# PIC32MK0256GPG064 register map
Vendor: Microchip
Registers are 32-bit, read-write, reset 0x0 unless marked. A register's access mark holds for its fields unless they carry their own. Addresses are absolute, and some are shared; only a register's first bit layout is shown; [hi:lo] are bit positions; {n}, {i} and the like mark numbered series.

## icd_jtag_bvci_upb
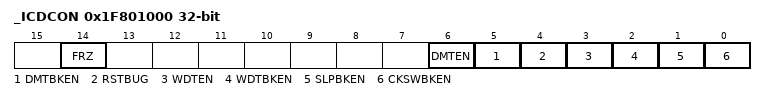
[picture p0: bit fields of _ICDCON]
0x1F801000 _ICDCON
  [14] FRZ, [6] DMTEN, [5] DMTBKEN, [4] RSTBUG, [3] WDTEN, [2] WDTBKEN, [1] SLPBKEN, [0] CKSWBKEN

## _DDPSTAT
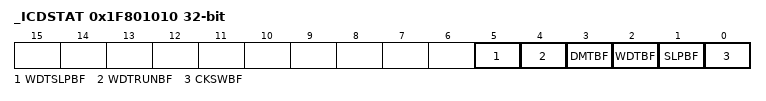
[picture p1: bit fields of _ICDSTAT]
0x1F801010 _ICDSTAT
  [5] WDTSLPBF, [4] WDTRUNBF, [3] DMTBF, [2] WDTBF, [1] SLPBF, [0] CKSWBF

## CRU
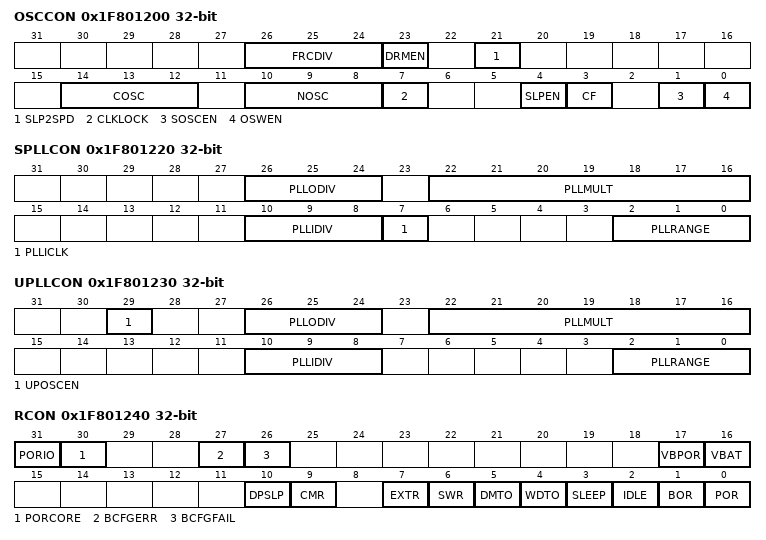
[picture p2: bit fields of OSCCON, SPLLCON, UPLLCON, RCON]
0x1F801200 OSCCON reset not defined — (power-on value -----0000-x------000-xxx0--00-x0)
  [26:24] FRCDIV, [23] DRMEN, [21] SLP2SPD, [14:12] COSC ro, [10:8] NOSC, [7] CLKLOCK, [4] SLPEN, [3] CF, [1] SOSCEN, [0] OSWEN
0x1F801210 OSCTUN
  [5:0] TUN
0x1F801220 SPLLCON reset not defined — (power-on value -----001-xxxxxxx-----xxx0----xxx)
  [26:24] PLLODIV, [22:16] PLLMULT, [10:8] PLLIDIV, [7] PLLICLK, [2:0] PLLRANGE
0x1F801230 UPLLCON reset not defined — (power-on value --x--001-xxxxxxx-----001-----xxx)
  [29] UPOSCEN, [26:24] PLLODIV, [22:16] PLLMULT, [10:8] PLLIDIV, [2:0] PLLRANGE
0x1F801240 RCON reset not defined — (power-on value 00--xx---------------x0-00000011)
  [31] PORIO
  [30] PORCORE
  [27] BCFGERR — Primary Configuration Registers Error Flag bit
    1=An error occurred during a read of the primary configuration registers; 0=No error occurred during a read of the primary configuration registers
  [26] BCFGFAIL — Primary/Secondary Configuration Registers Error Flag bit
    1=An error occurred during a read of the primary and alternate configuration registers; 0=No error occurred during a read of the primary and alternate configuration registers
  [17] VBPOR
  [16] VBAT
  [10] DPSLP
  [9] CMR
  [7] EXTR
  [6] SWR
  [5] DMTO
  [4] WDTO
  [3] SLEEP
  [2] IDLE
  [1] BOR
  [0] POR
0x1F801250 RSWRST wo
  [0] SWRST
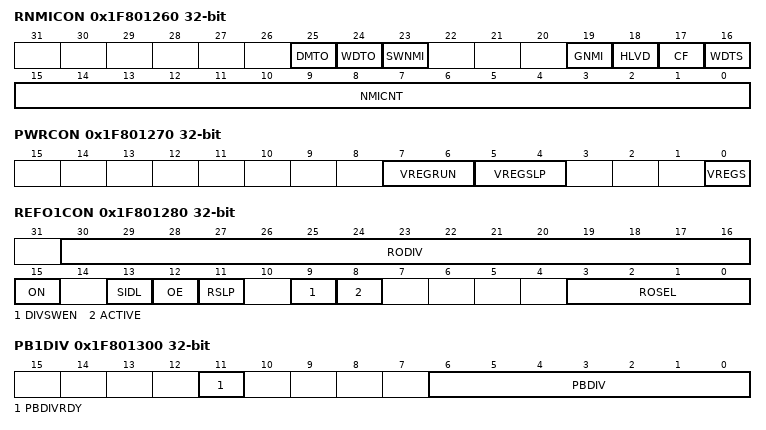
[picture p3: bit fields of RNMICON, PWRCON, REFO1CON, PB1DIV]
0x1F801260 RNMICON reset not defined — (power-on value ------0x0---0-000000000000000000)
  [25] DMTO, [24] WDTO, [23] SWNMI, [19] GNMI, [18] HLVD, [17] CF, [16] WDTS, [15:0] NMICNT
0x1F801270 PWRCON reset not defined — (power-on value ------------------------xxxx---0)
  [7:6] VREGRUN, [5:4] VREGSLP, [0] VREGS
0x1F801280 REFO1CON
  [30:16] RODIV, [15] ON, [13] SIDL, [12] OE, [11] RSLP, [9] DIVSWEN, [8] ACTIVE ro, [3:0] ROSEL
0x1F801290 REFO1TRIM
  [31:23] ROTRIM
0x1F801300 PB1DIV reset not defined — (power-on value --------------------1----xxxxxxx)
  [11] PBDIVRDY ro, [6:0] PBDIV
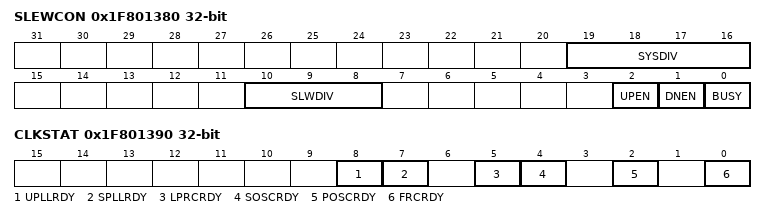
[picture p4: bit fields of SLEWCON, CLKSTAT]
0x1F801380 SLEWCON
  [19:16] SYSDIV, [10:8] SLWDIV, [2] UPEN, [1] DNEN, [0] BUSY
0x1F801390 CLKSTAT ro
  [8] UPLLRDY, [7] SPLLRDY, [5] LPRCRDY, [4] SOSCRDY, [2] POSCRDY, [0] FRCRDY

## WACJ_clk_cru_upb
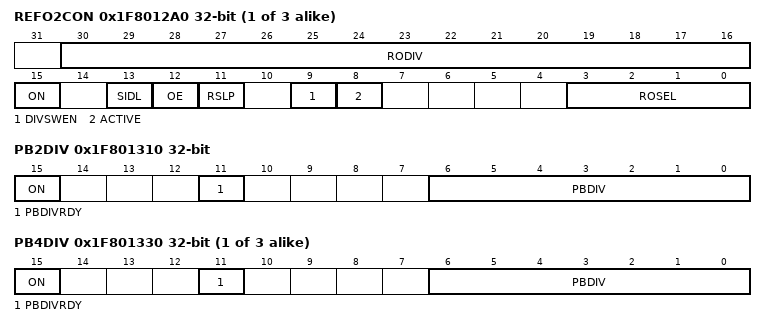
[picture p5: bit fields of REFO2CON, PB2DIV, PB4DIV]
{0x1F801260+0x20*i} REFO{i}CON (i=2..4)
  [30:16] RODIV, [15] ON, [13] SIDL, [12] OE, [11] RSLP, [9] DIVSWEN, [8] ACTIVE ro, [3:0] ROSEL
{0x1F801270+0x20*i} REFO{i}TRIM (i=2..4)
  [31:23] ROTRIM
0x1F801310 PB2DIV reset not defined — (power-on value ----------------1---1----xxxxxxx)
  [15] ON, [11] PBDIVRDY ro, [6:0] PBDIV
{0x1F8012F0+0x10*i} PB{i}DIV reset not defined (i=4..6) — (power-on value ----------------1---1----xxxxxxx)
  [15] ON, [11] PBDIVRDY ro, [6:0] PBDIV

## RPINRx
{0x1F801400+4i} INT{i}R (i=1..4)
  [3:0] INT{i}R
{0x1F801410+4i} T{i}CKR (i=2..9)
  [3:0] T{i}CKR
{0x1F801434+4i} IC{i}R (i=1..9)
  [3:0] IC{i}R
0x1F80145C OCFAR
  [3:0] OCFAR
0x1F801460 OCFBR
  [3:0] OCFBR
{0x1F80145C+8i} U{i}RXR (i=1..6)
  [3:0] U{i}RXR
{0x1F801460+8i} U{i}CTSR (i=1..6)
  [3:0] U{i}CTSR
{0x1F80148C+0xC*i} SDI{i}R (i=1..4)
  [3:0] SDI{i}R
{0x1F801490+0xC*i} SS{i}R (i=1..4)
  [3:0] SS{i}R
{0x1F801488+0xC*i} SCK{i}R (i=2..4)
  [3:0] SCK{i}R
0x1F8014C4 C1RXR
  [3:0] C1RXR
0x1F8014C8 C2RXR
  [3:0] C2RXR
0x1F8014CC REFIR
  [3:0] REFIR
0x1F8014D0 QEA1R
  [3:0] QEA1R
0x1F8014D4 QEB1R
  [3:0] QEB1R
0x1F8014D8 INDX1R
  [3:0] INDX1R
0x1F8014DC HOME1R
  [3:0] HOME1R
0x1F8014E0 QEA2R
  [3:0] QEA2R
0x1F8014E4 QEB2R
  [3:0] QEB2R
0x1F8014E8 INDX2R
  [3:0] INDX2R
0x1F8014EC HOME2R
  [3:0] HOME2R
0x1F8014F0 FLT1R
  [3:0] FLT1R
0x1F8014F4 FLT2R
  [3:0] FLT2R
{0x1F8014D0+4i} IC{i}R (i=10..16)
  [3:0] IC{i}R
0x1F801514 SCK5R
  [3:0] SCK5R
0x1F801518 SDI5R
  [3:0] SDI5R
0x1F80151C SS5R
  [3:0] SS5R
0x1F801520 SCK6R
  [3:0] SCK6R
0x1F801524 SDI6R
  [3:0] SDI6R
0x1F801528 SS6R
  [3:0] SS6R
0x1F80152C C3RXR
  [3:0] C3RXR
0x1F801530 C4RXR
  [3:0] C4RXR
{0x1F801504+0x10*i} QEA{i}R (i=3..6)
  [3:0] QEA{i}R
{0x1F801508+0x10*i} QEB{i}R (i=3..6)
  [3:0] QEB{i}R
{0x1F80150C+0x10*i} INDX{i}R (i=3..6)
  [3:0] INDX{i}R
{0x1F801510+0x10*i} HOME{i}R (i=3..6)
  [3:0] HOME{i}R
0x1F801574 CLCINAR
  [3:0] CLCINAR
0x1F801578 CLCINBR
  [3:0] CLCINBR
0x1F80157C CLCINCR
  [3:0] CLCINCR
0x1F801580 CLCINDR
  [3:0] CLCINDR
